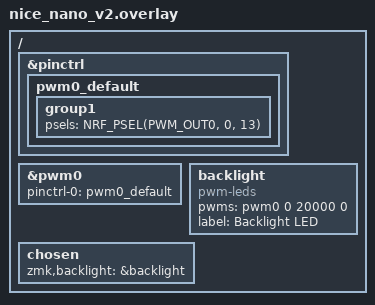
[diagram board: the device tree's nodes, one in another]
/ {
    &pinctrl {
        pwm0_default: pwm0_default {
            group1 {
                psels = <NRF_PSEL(PWM_OUT0, 0, 13)>;
            };
        };
    };
    
    &pwm0 {
        status = "okay";
        pinctrl-0 = <&pwm0_default>;
        pinctrl-names = "default";
    };

    backlight: backlight {
        compatible = "pwm-leds";
        pwms = <&pwm0 0 20000 0>;
        label = "Backlight LED";
    };

    chosen {
        zmk,backlight = &backlight;
    };
};
